AUTOSAR XML (schema 4-2-2)
package /STELLANTIS/EPT/ASWCs
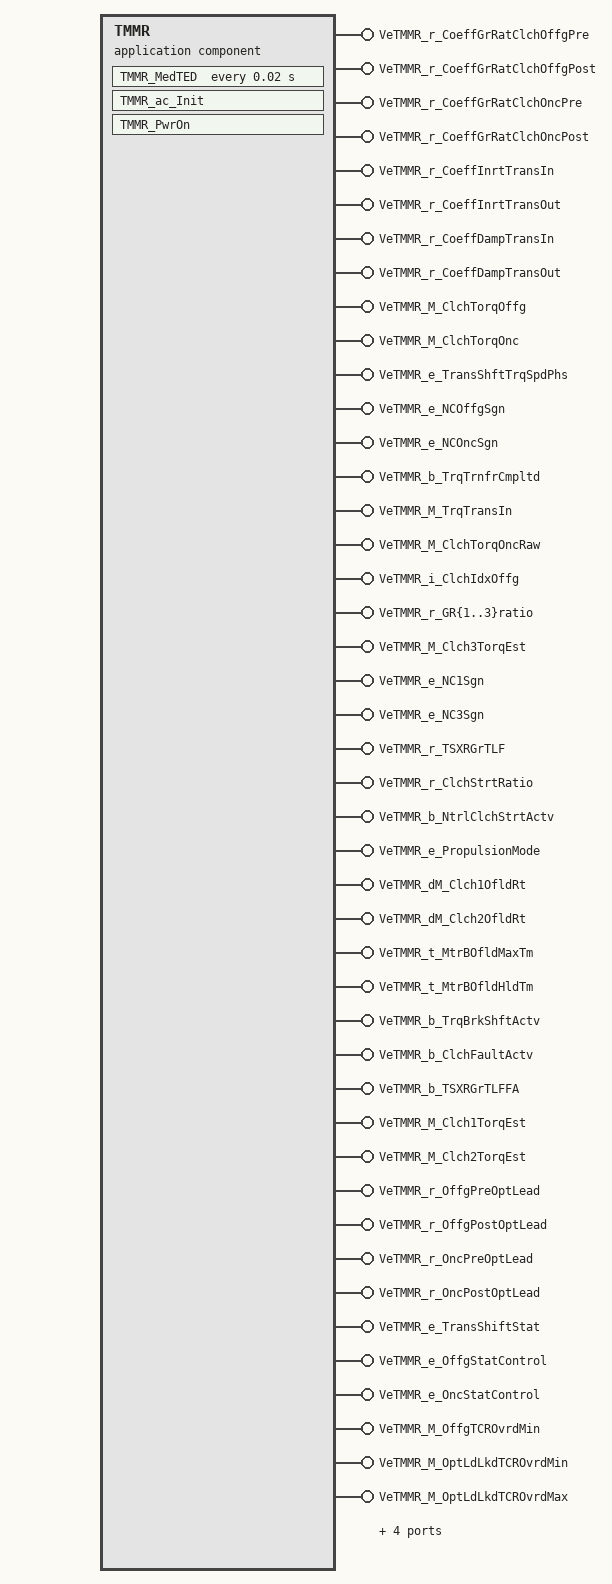
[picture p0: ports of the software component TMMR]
  application sw component type TMMR
    50 x provide port:
      VeTMMR_r_CoeffGrRatClchOffgPre: nonqueued-sender-com-spec{data-element=Value, init-value=0}, provided-interface=VeTMMR_r_CoeffGrRatClchOffgPre
      VeTMMR_r_CoeffGrRatClchOffgPost: nonqueued-sender-com-spec{data-element=Value, init-value=0}, provided-interface=VeTMMR_r_CoeffGrRatClchOffgPost
      VeTMMR_r_CoeffGrRatClchOncPre: nonqueued-sender-com-spec{data-element=Value, init-value=0}, provided-interface=VeTMMR_r_CoeffGrRatClchOncPre
      VeTMMR_r_CoeffGrRatClchOncPost: nonqueued-sender-com-spec{data-element=Value, init-value=0}, provided-interface=VeTMMR_r_CoeffGrRatClchOncPost
      VeTMMR_r_CoeffInrtTransIn: nonqueued-sender-com-spec{data-element=Value, init-value=0}, provided-interface=VeTMMR_r_CoeffInrtTransIn
      VeTMMR_r_CoeffInrtTransOut: nonqueued-sender-com-spec{data-element=Value, init-value=0}, provided-interface=VeTMMR_r_CoeffInrtTransOut
      VeTMMR_r_CoeffDampTransIn: nonqueued-sender-com-spec{data-element=Value, init-value=0}, provided-interface=VeTMMR_r_CoeffDampTransIn
      VeTMMR_r_CoeffDampTransOut: nonqueued-sender-com-spec{data-element=Value, init-value=0}, provided-interface=VeTMMR_r_CoeffDampTransOut
      VeTMMR_M_ClchTorqOffg: nonqueued-sender-com-spec{data-element=Value, init-value=0}, provided-interface=VeTMMR_M_ClchTorqOffg
      VeTMMR_M_ClchTorqOnc: nonqueued-sender-com-spec{data-element=Value, init-value=0}, provided-interface=VeTMMR_M_ClchTorqOnc
      VeTMMR_e_TransShftTrqSpdPhs: nonqueued-sender-com-spec{data-element=Value, init-value=CeTMMR_e_InactiveShiftInProgress}, provided-interface=VeTMMR_e_TransShftTrqSpdPhs
      VeTMMR_e_NCOffgSgn: nonqueued-sender-com-spec{data-element=Value, init-value=CeTMMR_e_UnknownNCSign}, provided-interface=VeTMMR_e_NCOffgSgn
      VeTMMR_e_NCOncSgn: nonqueued-sender-com-spec{data-element=Value, init-value=CeTMMR_e_UnknownNCSign}, provided-interface=VeTMMR_e_NCOncSgn
      VeTMMR_b_TrqTrnfrCmpltd: nonqueued-sender-com-spec{data-element=Value, init-value=0}, provided-interface=VeTMMR_b_TrqTrnfrCmpltd
      VeTMMR_M_TrqTransIn: nonqueued-sender-com-spec{data-element=Value, init-value=0}, provided-interface=VeTMMR_M_TrqTransIn
      VeTMMR_M_ClchTorqOncRaw: nonqueued-sender-com-spec{data-element=Value, init-value=0}, provided-interface=VeTMMR_M_ClchTorqOncRaw
      VeTMMR_i_ClchIdxOffg: nonqueued-sender-com-spec{data-element=Value, init-value=0}, provided-interface=VeTMMR_i_ClchIdxOffg
      VeTMMR_r_GR{1..3}ratio: nonqueued-sender-com-spec{data-element=Value, init-value=0}, provided-interface=VeTMMR_r_GR{1..3}ratio
      VeTMMR_M_Clch3TorqEst: nonqueued-sender-com-spec{data-element=Value, init-value=0}, provided-interface=VeTMMR_M_Clch3TorqEst
      VeTMMR_e_NC1Sgn: nonqueued-sender-com-spec{data-element=Value, init-value=CeTMMR_e_UnknownNCSign}, provided-interface=VeTMMR_e_NC1Sgn
      VeTMMR_e_NC3Sgn: nonqueued-sender-com-spec{data-element=Value, init-value=CeTMMR_e_UnknownNCSign}, provided-interface=VeTMMR_e_NC3Sgn
      VeTMMR_r_TSXRGrTLF: nonqueued-sender-com-spec{data-element=Value, init-value=0}, provided-interface=VeTMMR_r_TSXRGrTLF
      VeTMMR_r_ClchStrtRatio: nonqueued-sender-com-spec{data-element=Value, init-value=0}, provided-interface=VeTMMR_r_ClchStrtRatio
      VeTMMR_b_NtrlClchStrtActv: nonqueued-sender-com-spec{data-element=Value, init-value=0}, provided-interface=VeTMMR_b_NtrlClchStrtActv
      VeTMMR_e_PropulsionMode: nonqueued-sender-com-spec{data-element=Value, init-value=CeHSER_e_PropModeSNA}, provided-interface=VeTMMR_e_PropulsionMode
      VeTMMR_dM_Clch1OfldRt: nonqueued-sender-com-spec{data-element=Value, init-value=0}, provided-interface=VeTMMR_dM_Clch1OfldRt
      VeTMMR_dM_Clch2OfldRt: nonqueued-sender-com-spec{data-element=Value, init-value=0}, provided-interface=VeTMMR_dM_Clch2OfldRt
      VeTMMR_t_MtrBOfldMaxTm: nonqueued-sender-com-spec{data-element=Value, init-value=0}, provided-interface=VeTMMR_t_MtrBOfldMaxTm
      VeTMMR_t_MtrBOfldHldTm: nonqueued-sender-com-spec{data-element=Value, init-value=0}, provided-interface=VeTMMR_t_MtrBOfldHldTm
      VeTMMR_b_TrqBrkShftActv: nonqueued-sender-com-spec{data-element=Value, init-value=0}, provided-interface=VeTMMR_b_TrqBrkShftActv
      VeTMMR_b_ClchFaultActv: nonqueued-sender-com-spec{data-element=Value, init-value=0}, provided-interface=VeTMMR_b_ClchFaultActv
      VeTMMR_b_TSXRGrTLFFA: nonqueued-sender-com-spec{data-element=Value, init-value=0}, provided-interface=VeTMMR_b_TSXRGrTLFFA
      VeTMMR_M_Clch1TorqEst: nonqueued-sender-com-spec{data-element=Value, init-value=0}, provided-interface=VeTMMR_M_Clch1TorqEst
      VeTMMR_M_Clch2TorqEst: nonqueued-sender-com-spec{data-element=Value, init-value=0}, provided-interface=VeTMMR_M_Clch2TorqEst
      VeTMMR_r_OffgPreOptLead: nonqueued-sender-com-spec{data-element=Value, init-value=0}, provided-interface=VeTMMR_r_OffgPreOptLead
      VeTMMR_r_OffgPostOptLead: nonqueued-sender-com-spec{data-element=Value, init-value=0}, provided-interface=VeTMMR_r_OffgPostOptLead
      VeTMMR_r_OncPreOptLead: nonqueued-sender-com-spec{data-element=Value, init-value=0}, provided-interface=VeTMMR_r_OncPreOptLead
      VeTMMR_r_OncPostOptLead: nonqueued-sender-com-spec{data-element=Value, init-value=0}, provided-interface=VeTMMR_r_OncPostOptLead
      VeTMMR_e_TransShiftStat: nonqueued-sender-com-spec{data-element=Value, init-value=CeTMMR_e_SteadyState}, provided-interface=VeTMMR_e_TransShiftStat
      VeTMMR_e_OffgStatControl: nonqueued-sender-com-spec{data-element=Value, init-value=CeHSER_e_ONComing_C2CTrqPhs}, provided-interface=VeTMMR_e_OffgStatControl
      VeTMMR_e_OncStatControl: nonqueued-sender-com-spec{data-element=Value, init-value=CeHSER_e_ONComing_C2CTrqPhs}, provided-interface=VeTMMR_e_OncStatControl
      VeTMMR_M_OffgTCROvrdMin: nonqueued-sender-com-spec{data-element=Value, init-value=0}, provided-interface=VeTMMR_M_OffgTCROvrdMin
      VeTMMR_M_OptLdLkdTCROvrdMin: nonqueued-sender-com-spec{data-element=Value, init-value=0}, provided-interface=VeTMMR_M_OptLdLkdTCROvrdMin
      VeTMMR_M_OptLdLkdTCROvrdMax: nonqueued-sender-com-spec{data-element=Value, init-value=0}, provided-interface=VeTMMR_M_OptLdLkdTCROvrdMax
      VeTMMR_M_OffgTCROvrdMax: nonqueued-sender-com-spec{data-element=Value, init-value=0}, provided-interface=VeTMMR_M_OffgTCROvrdMax
      VeTMMR_b_InertiaTorqActive: nonqueued-sender-com-spec{data-element=Value, init-value=0}, provided-interface=VeTMMR_b_InertiaTorqActive
      VeTMMR_M_OncTCROvrdMin: nonqueued-sender-com-spec{data-element=Value, init-value=0}, provided-interface=VeTMMR_M_OncTCROvrdMin
      VeTMMR_M_OncTCROvrdMax: nonqueued-sender-com-spec{data-element=Value, init-value=0}, provided-interface=VeTMMR_M_OncTCROvrdMax
    behavior IB_TMMR: data-type-mapping=msADTtoIDTMapping, handle-termination-and-restart=NO-SUPPORT, included-data-type-set=data-type=[TeHSER_e_ClutchID, TeHSER_e_ShftInPrgs, TeTMMR_e_ClchTypeDef]
      timing event Event_MedTED: start-on-event=TMMR_MedTED, period=0.02
      init event Event_TMMR_ac_Init: start-on-event=TMMR_ac_Init
      init event Event_PwrOn: start-on-event=TMMR_PwrOn
      runnable TMMR_ac_Init
        data-send-points:
          23 x access:
            OUT_VeTMMR_r_GR{1..3}ratio_Value: accessed-variable=VeTMMR_r_GR{1..3}ratio.Value
            OUT_VeTMMR_M_Clch3TorqEst_Value: accessed-variable=VeTMMR_M_Clch3TorqEst.Value
            OUT_VeTMMR_e_NC1Sgn_Value: accessed-variable=VeTMMR_e_NC1Sgn.Value
            OUT_VeTMMR_e_NC3Sgn_Value: accessed-variable=VeTMMR_e_NC3Sgn.Value
            OUT_VeTMMR_r_TSXRGrTLF_Value: accessed-variable=VeTMMR_r_TSXRGrTLF.Value
            OUT_VeTMMR_r_ClchStrtRatio_Value: accessed-variable=VeTMMR_r_ClchStrtRatio.Value
            OUT_VeTMMR_b_NtrlClchStrtActv_Value: accessed-variable=VeTMMR_b_NtrlClchStrtActv.Value
            OUT_VeTMMR_e_PropulsionMode_Value: accessed-variable=VeTMMR_e_PropulsionMode.Value
            OUT_VeTMMR_dM_Clch1OfldRt_Value: accessed-variable=VeTMMR_dM_Clch1OfldRt.Value
            OUT_VeTMMR_dM_Clch2OfldRt_Value: accessed-variable=VeTMMR_dM_Clch2OfldRt.Value
            OUT_VeTMMR_t_MtrBOfldMaxTm_Value: accessed-variable=VeTMMR_t_MtrBOfldMaxTm.Value
            OUT_VeTMMR_t_MtrBOfldHldTm_Value: accessed-variable=VeTMMR_t_MtrBOfldHldTm.Value
            OUT_VeTMMR_b_TrqBrkShftActv_Value: accessed-variable=VeTMMR_b_TrqBrkShftActv.Value
            OUT_VeTMMR_b_ClchFaultActv_Value: accessed-variable=VeTMMR_b_ClchFaultActv.Value
            OUT_VeTMMR_b_TSXRGrTLFFA_Value: accessed-variable=VeTMMR_b_TSXRGrTLFFA.Value
            OUT_VeTMMR_e_TransShftTrqSpdPhs_Value: accessed-variable=VeTMMR_e_TransShftTrqSpdPhs.Value
            OUT_VeTMMR_e_NCOffgSgn_Value: accessed-variable=VeTMMR_e_NCOffgSgn.Value
            OUT_VeTMMR_e_NCOncSgn_Value: accessed-variable=VeTMMR_e_NCOncSgn.Value
            OUT_VeTMMR_e_TransShiftStat_Value: accessed-variable=VeTMMR_e_TransShiftStat.Value
            OUT_VeTMMR_e_OffgStatControl_Value: accessed-variable=VeTMMR_e_OffgStatControl.Value
            OUT_VeTMMR_e_OncStatControl_Value: accessed-variable=VeTMMR_e_OncStatControl.Value
      runnable TMMR_PwrOn
        data-send-points:
          50 x access:
            OUT_VeTMMR_r_CoeffGrRatClchOffgPre_Value: accessed-variable=VeTMMR_r_CoeffGrRatClchOffgPre.Value
            OUT_VeTMMR_M_ClchTorqOffg_Value: accessed-variable=VeTMMR_M_ClchTorqOffg.Value
            OUT_VeTMMR_M_ClchTorqOnc_Value: accessed-variable=VeTMMR_M_ClchTorqOnc.Value
            OUT_VeTMMR_e_TransShftTrqSpdPhs_Value: accessed-variable=VeTMMR_e_TransShftTrqSpdPhs.Value
            OUT_VeTMMR_e_NCOffgSgn_Value: accessed-variable=VeTMMR_e_NCOffgSgn.Value
            OUT_VeTMMR_e_NCOncSgn_Value: accessed-variable=VeTMMR_e_NCOncSgn.Value
            OUT_VeTMMR_b_TrqTrnfrCmpltd_Value: accessed-variable=VeTMMR_b_TrqTrnfrCmpltd.Value
            OUT_VeTMMR_M_TrqTransIn_Value: accessed-variable=VeTMMR_M_TrqTransIn.Value
            OUT_VeTMMR_M_ClchTorqOncRaw_Value: accessed-variable=VeTMMR_M_ClchTorqOncRaw.Value
            OUT_VeTMMR_i_ClchIdxOffg_Value: accessed-variable=VeTMMR_i_ClchIdxOffg.Value
            OUT_VeTMMR_r_CoeffGrRatClchOffgPost_Value: accessed-variable=VeTMMR_r_CoeffGrRatClchOffgPost.Value
            OUT_VeTMMR_r_CoeffGrRatClchOncPre_Value: accessed-variable=VeTMMR_r_CoeffGrRatClchOncPre.Value
            OUT_VeTMMR_r_CoeffGrRatClchOncPost_Value: accessed-variable=VeTMMR_r_CoeffGrRatClchOncPost.Value
            OUT_VeTMMR_r_CoeffInrtTransIn_Value: accessed-variable=VeTMMR_r_CoeffInrtTransIn.Value
            OUT_VeTMMR_r_CoeffInrtTransOut_Value: accessed-variable=VeTMMR_r_CoeffInrtTransOut.Value
            OUT_VeTMMR_r_CoeffDampTransIn_Value: accessed-variable=VeTMMR_r_CoeffDampTransIn.Value
            OUT_VeTMMR_r_CoeffDampTransOut_Value: accessed-variable=VeTMMR_r_CoeffDampTransOut.Value
            OUT_VeTMMR_r_GR{1..3}ratio_Value: accessed-variable=VeTMMR_r_GR{1..3}ratio.Value
            OUT_VeTMMR_M_Clch{1..3}TorqEst_Value: accessed-variable=VeTMMR_M_Clch{1..3}TorqEst.Value
            OUT_VeTMMR_e_NC1Sgn_Value: accessed-variable=VeTMMR_e_NC1Sgn.Value
            OUT_VeTMMR_e_NC3Sgn_Value: accessed-variable=VeTMMR_e_NC3Sgn.Value
            OUT_VeTMMR_r_TSXRGrTLF_Value: accessed-variable=VeTMMR_r_TSXRGrTLF.Value
            OUT_VeTMMR_r_ClchStrtRatio_Value: accessed-variable=VeTMMR_r_ClchStrtRatio.Value
            OUT_VeTMMR_b_NtrlClchStrtActv_Value: accessed-variable=VeTMMR_b_NtrlClchStrtActv.Value
            OUT_VeTMMR_e_PropulsionMode_Value: accessed-variable=VeTMMR_e_PropulsionMode.Value
            OUT_VeTMMR_dM_Clch1OfldRt_Value: accessed-variable=VeTMMR_dM_Clch1OfldRt.Value
            OUT_VeTMMR_dM_Clch2OfldRt_Value: accessed-variable=VeTMMR_dM_Clch2OfldRt.Value
            OUT_VeTMMR_t_MtrBOfldMaxTm_Value: accessed-variable=VeTMMR_t_MtrBOfldMaxTm.Value
            OUT_VeTMMR_t_MtrBOfldHldTm_Value: accessed-variable=VeTMMR_t_MtrBOfldHldTm.Value
            OUT_VeTMMR_b_TrqBrkShftActv_Value: accessed-variable=VeTMMR_b_TrqBrkShftActv.Value
            OUT_VeTMMR_b_ClchFaultActv_Value: accessed-variable=VeTMMR_b_ClchFaultActv.Value
            OUT_VeTMMR_b_TSXRGrTLFFA_Value: accessed-variable=VeTMMR_b_TSXRGrTLFFA.Value
            OUT_VeTMMR_r_OffgPreOptLead_Value: accessed-variable=VeTMMR_r_OffgPreOptLead.Value
            OUT_VeTMMR_r_OffgPostOptLead_Value: accessed-variable=VeTMMR_r_OffgPostOptLead.Value
            OUT_VeTMMR_r_OncPreOptLead_Value: accessed-variable=VeTMMR_r_OncPreOptLead.Value
            OUT_VeTMMR_r_OncPostOptLead_Value: accessed-variable=VeTMMR_r_OncPostOptLead.Value
            OUT_VeTMMR_e_TransShiftStat_Value: accessed-variable=VeTMMR_e_TransShiftStat.Value
            OUT_VeTMMR_e_OffgStatControl_Value: accessed-variable=VeTMMR_e_OffgStatControl.Value
            OUT_VeTMMR_e_OncStatControl_Value: accessed-variable=VeTMMR_e_OncStatControl.Value
            OUT_VeTMMR_M_OffgTCROvrdMin_Value: accessed-variable=VeTMMR_M_OffgTCROvrdMin.Value
            OUT_VeTMMR_M_OptLdLkdTCROvrdMin_Value: accessed-variable=VeTMMR_M_OptLdLkdTCROvrdMin.Value
            OUT_VeTMMR_M_OffgTCROvrdMax_Value: accessed-variable=VeTMMR_M_OffgTCROvrdMax.Value
            OUT_VeTMMR_M_OptLdLkdTCROvrdMax_Value: accessed-variable=VeTMMR_M_OptLdLkdTCROvrdMax.Value
            OUT_VeTMMR_b_InertiaTorqActive_Value: accessed-variable=VeTMMR_b_InertiaTorqActive.Value
            OUT_VeTMMR_M_OncTCROvrdMin_Value: accessed-variable=VeTMMR_M_OncTCROvrdMin.Value
            OUT_VeTMMR_M_OncTCROvrdMax_Value: accessed-variable=VeTMMR_M_OncTCROvrdMax.Value
      runnable TMMR_MedTED
        data-send-points:
          33 x access:
            OUT_VeTMMR_r_CoeffGrRatClchOffgPre_Value: accessed-variable=VeTMMR_r_CoeffGrRatClchOffgPre.Value
            OUT_VeTMMR_M_ClchTorqOffg_Value: accessed-variable=VeTMMR_M_ClchTorqOffg.Value
            OUT_VeTMMR_M_ClchTorqOnc_Value: accessed-variable=VeTMMR_M_ClchTorqOnc.Value
            OUT_VeTMMR_e_TransShftTrqSpdPhs_Value: accessed-variable=VeTMMR_e_TransShftTrqSpdPhs.Value
            OUT_VeTMMR_e_NCOffgSgn_Value: accessed-variable=VeTMMR_e_NCOffgSgn.Value
            OUT_VeTMMR_e_NCOncSgn_Value: accessed-variable=VeTMMR_e_NCOncSgn.Value
            OUT_VeTMMR_b_TrqTrnfrCmpltd_Value: accessed-variable=VeTMMR_b_TrqTrnfrCmpltd.Value
            OUT_VeTMMR_M_TrqTransIn_Value: accessed-variable=VeTMMR_M_TrqTransIn.Value
            OUT_VeTMMR_M_ClchTorqOncRaw_Value: accessed-variable=VeTMMR_M_ClchTorqOncRaw.Value
            OUT_VeTMMR_i_ClchIdxOffg_Value: accessed-variable=VeTMMR_i_ClchIdxOffg.Value
            OUT_VeTMMR_r_CoeffGrRatClchOffgPost_Value: accessed-variable=VeTMMR_r_CoeffGrRatClchOffgPost.Value
            OUT_VeTMMR_r_CoeffGrRatClchOncPre_Value: accessed-variable=VeTMMR_r_CoeffGrRatClchOncPre.Value
            OUT_VeTMMR_r_CoeffGrRatClchOncPost_Value: accessed-variable=VeTMMR_r_CoeffGrRatClchOncPost.Value
            OUT_VeTMMR_r_CoeffInrtTransIn_Value: accessed-variable=VeTMMR_r_CoeffInrtTransIn.Value
            OUT_VeTMMR_r_CoeffInrtTransOut_Value: accessed-variable=VeTMMR_r_CoeffInrtTransOut.Value
            OUT_VeTMMR_r_CoeffDampTransIn_Value: accessed-variable=VeTMMR_r_CoeffDampTransIn.Value
            OUT_VeTMMR_r_CoeffDampTransOut_Value: accessed-variable=VeTMMR_r_CoeffDampTransOut.Value
            OUT_VeTMMR_M_Clch1TorqEst_Value: accessed-variable=VeTMMR_M_Clch1TorqEst.Value
            OUT_VeTMMR_M_Clch2TorqEst_Value: accessed-variable=VeTMMR_M_Clch2TorqEst.Value
            OUT_VeTMMR_r_OffgPreOptLead_Value: accessed-variable=VeTMMR_r_OffgPreOptLead.Value
            OUT_VeTMMR_r_OffgPostOptLead_Value: accessed-variable=VeTMMR_r_OffgPostOptLead.Value
            OUT_VeTMMR_r_OncPreOptLead_Value: accessed-variable=VeTMMR_r_OncPreOptLead.Value
            OUT_VeTMMR_r_OncPostOptLead_Value: accessed-variable=VeTMMR_r_OncPostOptLead.Value
            OUT_VeTMMR_e_TransShiftStat_Value: accessed-variable=VeTMMR_e_TransShiftStat.Value
            OUT_VeTMMR_e_OffgStatControl_Value: accessed-variable=VeTMMR_e_OffgStatControl.Value
            OUT_VeTMMR_e_OncStatControl_Value: accessed-variable=VeTMMR_e_OncStatControl.Value
            OUT_VeTMMR_M_OffgTCROvrdMax_Value: accessed-variable=VeTMMR_M_OffgTCROvrdMax.Value
            OUT_VeTMMR_M_OptLdLkdTCROvrdMax_Value: accessed-variable=VeTMMR_M_OptLdLkdTCROvrdMax.Value
            OUT_VeTMMR_M_OffgTCROvrdMin_Value: accessed-variable=VeTMMR_M_OffgTCROvrdMin.Value
            OUT_VeTMMR_M_OptLdLkdTCROvrdMin_Value: accessed-variable=VeTMMR_M_OptLdLkdTCROvrdMin.Value
            OUT_VeTMMR_b_InertiaTorqActive_Value: accessed-variable=VeTMMR_b_InertiaTorqActive.Value
            OUT_VeTMMR_M_OncTCROvrdMax_Value: accessed-variable=VeTMMR_M_OncTCROvrdMax.Value
            OUT_VeTMMR_M_OncTCROvrdMin_Value: accessed-variable=VeTMMR_M_OncTCROvrdMin.Value
      variation point proxy Variant_TMMR_FUNC_Enable: category=CONDITION, condition-access=0
      variation point proxy Variant_TMMR_FUNC_EnableProcClchTorq: category=CONDITION, condition-access=0
